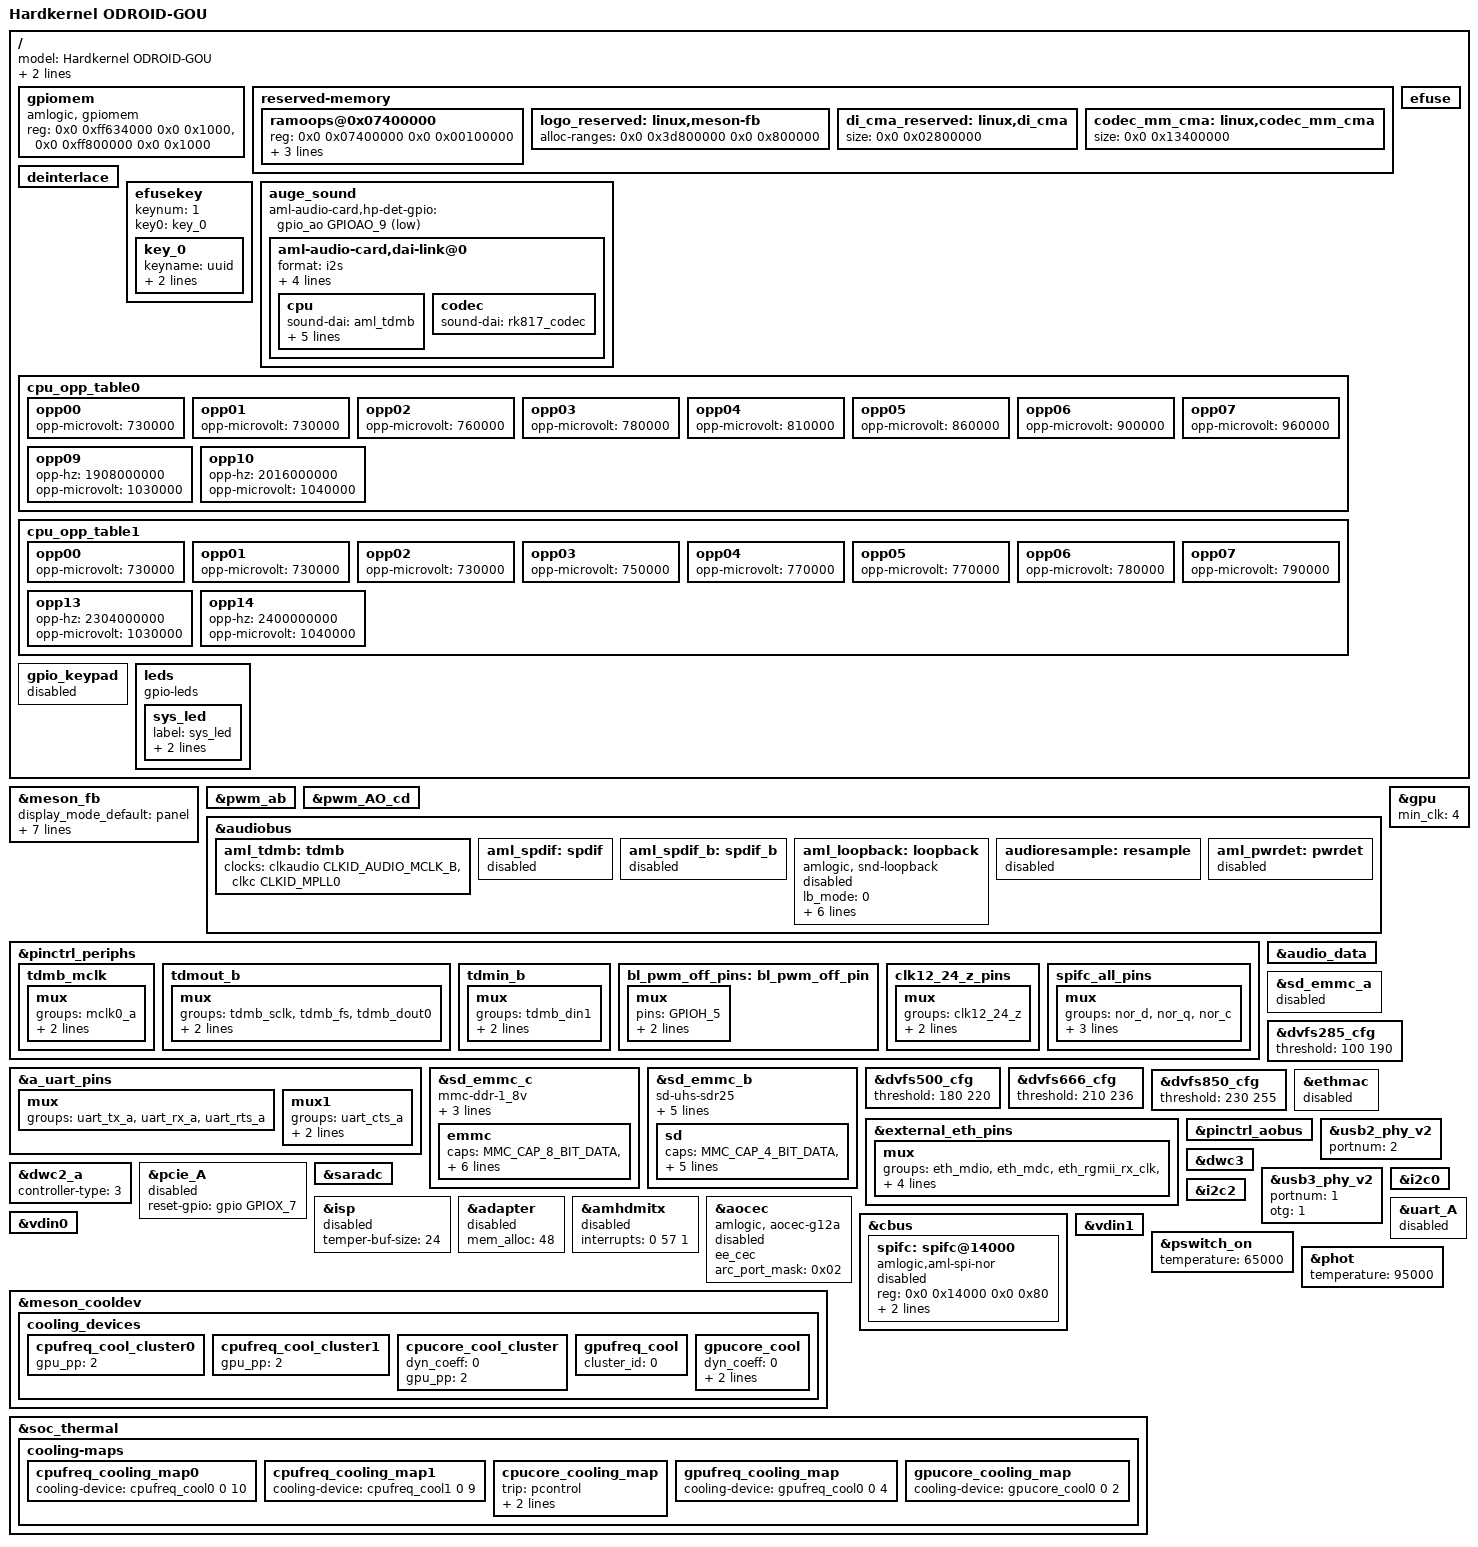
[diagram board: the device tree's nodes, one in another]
// All g12b devices should base on either coreelec_g12b.dtsi or coreelec_g12b_a.dtsi
#include "coreelec_g12b.dtsi"
// OGU specific: Power Management Integrated Controller
#include "meson64_gou_pmic.dtsi"
// OGU specific: LCD panel
#include "meson64_gou_panel.dtsi"
// OGU specific: GPIO Joypad
#include "meson64_gou_joypad.dtsi"

/ {
	model = "Hardkernel ODROID-GOU";
	coreelec-dt-id = "g12b_s922x_odroid_go_ultra"; // Yeah we will still use coreelec-dt-id, never re-invent the wheel huh?
	amlogic-dt-id = "g12b_ogu";

	/delete-node/ bt-dev; // No BT or Wi-Fi included
	/delete-node/ wifi;
	/delete-node/ wifi_pwm_conf;
	/delete-node/ adc_keypad;
	/delete-node/ unifykey;
	// /delete-node/ rtc;
	/delete-node/ videosync;
	/delete-node/ dummy_venc;
	/delete-node/ video_composer;
	/delete-node/ meson_uvm;
	/delete-node/ vcodec_dec;
	/delete-node/ jpegenc;
	/delete-node/ gpioleds;
	/delete-node/ cvbsout;
	/delete-node/ linux,picdec;
	/delete-node/ picdec;
	/delete-node/ multi-di;
	/delete-node/ meson-ir;
	/delete-node/ meson-remote;
	/delete-node/ openvfd;
	/delete-node/ amvideocap;

	gpiomem {
		compatible = "amlogic, gpiomem";
		reg = <0x0 0xff634000 0x0 0x1000>,	/* GPIO banks */
			<0x0 0xff800000 0x0 0x1000>;	/* GPIO_AO bank */
		status = "okay";
	};

	reserved-memory {
		#address-cells = <2>;
		#size-cells = <2>;
		ranges;

		/* global autoconfigured region for contiguous allocations */
		ramoops@0x07400000 {
			reg = <0x0 0x07400000 0x0 0x00100000>;
			record-size = <0x8000>;
			console-size = <0x8000>;
			ftrace-size = <0x40000>;
		};

		logo_reserved:linux,meson-fb {
			alloc-ranges = <0x0 0x3d800000 0x0 0x800000>;
		};

		/*di CMA pool */
		di_cma_reserved:linux,di_cma {
			/* buffer_size = 3621952(yuv422 8bit)
			 *  | 4736064(yuv422 10bit)
			 *  | 4074560(yuv422 10bit full pack mode)
			 * 10x3621952=34.6M(0x23) support 8bit
			 * 10x4736064=45.2M(0x2e) support 12bit
			 * 10x4074560=40M(0x28) support 10bit
			 */
			size = <0x0 0x02800000>;
		};

		codec_mm_cma:linux,codec_mm_cma {
			/* ion_codec_mm max can alloc size 80M*/
			size = <0x0 0x13400000>;
		};	
	};

	deinterlace {
		status = "okay";
	};

	efuse: efuse{
		status = "okay";
	};

	efusekey:efusekey{
		keynum = <1>;
		key0 = <&key_0>;
		/delete-property/ key1;
		/delete-property/ key2;
		/delete-property/ key3;
		/delete-node/ key_1;
		/delete-node/ key_2;
		/delete-node/ key_3;

		key_0: key_0 {
			keyname = "uuid";
			offset = <0>;
			size = <32>;
		};
	};//End efusekey

	/* Audio Related start */
	auge_sound {
		aml-audio-card,hp-det-gpio = <&gpio_ao GPIOAO_9 GPIO_ACTIVE_LOW>;
		/delete-property/ avout_mute-gpios;
		/delete-node/ aml-audio-card,dai-link@1;
		/delete-node/ aml-audio-card,dai-link@2;
		/delete-node/ aml-audio-card,dai-link@3;
		aml-audio-card,dai-link@0 {
			format = "i2s";
			mclk-fs = <256>;
			bitclock-master = <&aml_tdmb>;
			frame-master = <&aml_tdmb>;
			continuous-clock;

			cpu {
				sound-dai = <&aml_tdmb>;
				dai-tdm-slot-tx-mask = <1 1>;
				dai-tdm-slot-rx-mask = <1 1>;
				dai-tdm-slot-num = <2>;
				dai-tdm-slot-width = <32>;
				system-clock-frequency = <12288000>;
			};
			codec {
				sound-dai = <&rk817_codec>;
			};
		};
	};
	/* Audio Related end */

	cpu_opp_table0: cpu_opp_table0 {
		opp00 {
			opp-microvolt = <730000>;
		};
		opp01 {
			opp-microvolt = <730000>;
		};
		opp02 {
			opp-microvolt = <760000>;
		};
		opp03 {
			opp-microvolt = <780000>;
		};
		opp04 {
			opp-microvolt = <810000>;
		};
		opp05 {
			opp-microvolt = <860000>;
		};
		opp06 {
			opp-microvolt = <900000>;
		};
		opp07 {
			opp-microvolt = <960000>;
		};
		opp09 {
			opp-hz = /bits/ 64 <1908000000>;
			opp-microvolt = <1030000>;
		};
		opp10 {
			opp-hz = /bits/ 64 <2016000000>;
			opp-microvolt = <1040000>;
		};
	};

	cpu_opp_table1: cpu_opp_table1 {
		opp00 {
			opp-microvolt = <730000>;
		};
		opp01 {
			opp-microvolt = <730000>;
		};
		opp02 {
			opp-microvolt = <730000>;
		};
		opp03 {
			opp-microvolt = <750000>;
		};
		opp04 {
			opp-microvolt = <770000>;
		};
		opp05 {
			opp-microvolt = <770000>;
		};
		opp06 {
			opp-microvolt = <780000>;
		};
		opp07 {
			opp-microvolt = <790000>;
		};
		opp13 {
			opp-hz = /bits/ 64 <2304000000>;
			opp-microvolt = <1030000>;
		};
		opp14 {
			opp-hz = /bits/ 64 <2400000000>;
			opp-microvolt = <1040000>;
		};
	};

	gpio_keypad {
		status = "disabled";
	};

	leds {
		compatible = "gpio-leds";
		status = "okay";
		sys_led {
			label="sys_led";
			gpios=<&gpio_ao GPIOAO_11 GPIO_ACTIVE_HIGH>;
			linux,default-trigger = "heartbeat";
		};
	};
}; /* end of / */

&meson_fb {
	status = "okay";
	display_mode_default = "panel";
	display_size_default = <480 854 480 1708 32>;
	mem_size = <0x00800000 0x4b80000 0x100000 0x100000 0x800000>;
	logo_addr = "0x3d800000";
	mem_alloc = <1>;
	pxp_mode = <0>; /** 0:normal mode 1:pxp mode */
	4k2k_fb = <0>;
};

&pwm_ab {
	status = "okay";
};

&pwm_AO_cd {
	status = "okay";
};

&audiobus {
	/* tdmb to internal DAC output*/
	/delete-node/ loopback@0;
	/delete-node/ i2s2hdmi;
	aml_tdmb: tdmb {
		clocks = <&clkaudio CLKID_AUDIO_MCLK_B
				&clkc CLKID_MPLL0>;
		clock-names = "mclk", "clk_srcpll";
		/delete-property/ samesource_sel;
	};
	aml_spdif: spdif {
		status = "disabled";
	};
	aml_spdif_b: spdif_b {
		status = "disabled";
	};
	aml_loopback: loopback {
		compatible = "amlogic, snd-loopback";
		/*
		 * 0: out rate = in data rate;
		 * 1: out rate = loopback data rate;
		 */
		lb_mode = <0>;

		/* datain src
		 * 0: tdmin_a;
		 * 1: tdmin_b;
		 * 2: tdmin_c;
		 * 3: spdifin;
		 * 4: pdmin;
		 */
		datain_src = <4>;
		datain_chnum = <8>;
		datain_chmask = <0x3f>;

		/* tdmin_lb src
		 * 0: tdmoutA
		 * 1: tdmoutB
		 * 2: tdmoutC
		 * 3: PAD_tdminA
		 * 4: PAD_tdminB
		 * 5: PAD_tdminC
		 */
		datalb_src = <2>;
		datalb_chnum = <8>;
		datalb_chmask = <0x3>;

		status = "disabled";
	};

	audioresample: resample {
		status = "disabled";
	};
	aml_pwrdet: pwrdet {
		status = "disabled";
	};
}; /* end of audiobus */

&pinctrl_periphs {
	tdmb_mclk: tdmb_mclk {
		mux { /* GPIOA_0 */
			groups = "mclk0_a";
			function = "mclk0";
			drive-strength = <2>;
		};
	};
	tdmout_b: tdmout_b {
		mux { /* GPIOA_1, GPIOA_2, GPIOA_3 */
			groups = "tdmb_sclk",
				"tdmb_fs",
				"tdmb_dout0";
			function = "tdmb_out";
			drive-strength = <2>;
		};
	};
	tdmin_b:tdmin_b {
		mux { /* GPIOA_4 */
			groups = "tdmb_din1";
			function = "tdmb_in";
			drive-strength = <2>;
		};
	};

	bl_pwm_off_pins:bl_pwm_off_pin {
		mux {
			pins = "GPIOH_5";
			function = "gpio_periphs";
			output-high;
		};
	};

	clk12_24_z_pins:clk12_24_z_pins {
		mux {
			groups = "clk12_24_z";
			function = "clk12_24_ee";
			drive-strength = <3>;
		};
	};

	spifc_all_pins: spifc_all_pins {
		mux {
			groups = "nor_d",
				"nor_q",
				"nor_c";
			function = "nor";
			input-enable;
			bias-pull-up;
		};
	};
}; /* end of pinctrl_periphs */

&a_uart_pins {
	mux {
		groups = "uart_tx_a",
			"uart_rx_a",
			"uart_rts_a";
	};
	mux1 {
		groups = "uart_cts_a";
		function = "uart_a";
		bias-pull-down;
	};
};

&audio_data {
	status = "okay";
};

&sd_emmc_c {
	status = "okay";
	mmc-ddr-1_8v;
	mmc-hs200-1_8v;
	vmmc-supply = <&vcc_sd>;
	vqmmc-supply = <&vddio_ao1v8>;
	emmc {
		caps = "MMC_CAP_8_BIT_DATA",
			 "MMC_CAP_MMC_HIGHSPEED",
			 "MMC_CAP_SD_HIGHSPEED",
			 "MMC_CAP_NONREMOVABLE",
			 "MMC_CAP_HW_RESET",
			 "MMC_CAP_ERASE",
			 "MMC_CAP_CMD23";
		caps2 = "MMC_CAP2_HS200_1_8V_SDR",
			"MMC_CAP2_BROKEN_VOLTAGE";
		hw_reset = <&gpio BOOT_12 GPIO_ACTIVE_HIGH>;
	};
};

&sd_emmc_b {
	status = "okay";
	sd-uhs-sdr25;
	sd-uhs-sdr50;
	sd-uhs-sdr104;
	max-frequency = <200000000>;
	vmmc-supply = <&vcc_sd>;
	vqmmc-supply = <&vddio_c>;
	sd {
		caps = "MMC_CAP_4_BIT_DATA",
			 "MMC_CAP_MMC_HIGHSPEED",
			 "MMC_CAP_SD_HIGHSPEED",
			 "MMC_CAP_UHS_SDR25",
			 "MMC_CAP_UHS_SDR50",
			 "MMC_CAP_UHS_SDR104",
			 "MMC_CAP_ERASE",
			 "MMC_CAP_CMD23";
		f_max = <200000000>;
	};
};

&sd_emmc_a {
	status = "disabled";
	/delete-node/ sdio;
};

&gpu {
	min_clk = <4>;
};

&dvfs285_cfg {
   threshold = <100 190>;
};

&dvfs500_cfg {
   threshold = <180 220>;
};

&dvfs666_cfg {
   threshold = <210 236>;
};

&dvfs850_cfg {
   threshold = <230 255>;
};

&ethmac {
	status = "disabled";
	/delete-property/ mc_val;
	/delete-property/ internal_phy;
	/delete-property/ pinctrl-names;
	/delete-property/ pinctrl-0;
};

&external_eth_pins {
	mux {
		groups = "eth_mdio",
		"eth_mdc",
		"eth_rgmii_rx_clk",
		"eth_rx_dv",
		"eth_rxd0",
		"eth_rxd1",
		"eth_rxd2_rgmii",
		"eth_rxd3_rgmii",
		"eth_rgmii_tx_clk",
		"eth_txen",
		"eth_txd0",
		"eth_txd1",
		"eth_txd2_rgmii",
		"eth_txd3_rgmii";
	};
};

&pinctrl_aobus {
	/delete-node/ spdifout;
	/delete-node/ spdifout_a_mute;
};

&aml_spdif {
	/delete-property/ pinctrl-0;
	/delete-property/ pinctrl-1;
};

&usb2_phy_v2 {
	status = "okay";
	portnum = <2>;
};

&dwc3 {
	status = "okay";
};

&dwc2_a {
	status = "okay";
	/** 0: normal, 1: otg+dwc3 host only, 2: otg+dwc3 device only*/
	controller-type = <3>;
};

&pcie_A {
	reset-gpio = <&gpio GPIOX_7 GPIO_ACTIVE_HIGH>;
	status = "disabled";
	clock-names = "pcie_refpll",
				"pcie",
				"pcie_phy";
};

&usb3_phy_v2 {
	status = "okay";
	portnum = <1>;
	otg = <1>;
	/delete-property/ gpio-vbus-power;
	/delete-property/ gpios;
};

&saradc {
	status = "okay";
};

&i2c0 {
	/delete-property/ pinctrl-names;
	/delete-property/ pinctrl-0;
	/delete-property/ clock-frequency;
};

&i2c2 {
	/delete-property/ pinctrl-names;
	/delete-property/ pinctrl-0;
	/delete-property/ clock-frequency;
};

&isp {
	status = "disabled";
	temper-buf-size = <24>;
	/delete-property/ temper-line-offset;
	/delete-property/ temper-frame-num;
	/delete-property/ temper-frame-size;
	/delete-property/ memory-region;
};

&adapter {
	status = "disabled";
	mem_alloc = <48>;
	/delete-property/ memory-region;
};

&amhdmitx {
	status = "disabled";
	interrupts = <0 57 1>;
	interrupt-names = "hdmitx_hpd";
};

&aocec {
	status = "disabled";
	compatible = "amlogic, aocec-g12a";
	ee_cec;
	arc_port_mask = <0x02>;
	/delete-property/ output;
};

&cbus {
	spifc: spifc@14000 {
		status = "disabled";
		compatible = "amlogic,aml-spi-nor";
		reg = <0x0 0x14000 0x0 0x80>;
		pinctrl-names = "default";
		pinctrl-0 = <&spifc_all_pins>;
		clocks = <&clkc 11>;
		clock-names = "core";
   };
};

&uart_A {
	status = "disabled";
};

&vdin0 {
	/delete-property/ cma_size;
	/delete-property/ tv_bit_mode;
};

&vdin1 {
	/delete-property/ memory-region;
	/delete-property/ tv_bit_mode;
};

&meson_cooldev {
	cooling_devices {
		cpufreq_cool_cluster0 {
			gpu_pp = <2>;
		};
		cpufreq_cool_cluster1 {
			gpu_pp = <2>;
		};
		cpucore_cool_cluster {
			dyn_coeff = <0>;
			gpu_pp = <2>;
		};
		gpufreq_cool {
			cluster_id = <0>;
		};
		gpucore_cool {
			dyn_coeff = <0>;
			cluster_id = <0>;
			gpu_pp = <2>;
		};
	};
};

&pswitch_on {
	temperature = <65000>;
};

&phot {
	temperature = <95000>;
};

&soc_thermal {
	cooling-maps {
		/delete-node/ cpucore_cooling_map0;
		cpufreq_cooling_map0 {
			cooling-device = <&cpufreq_cool0 0 10>;
		};
		cpufreq_cooling_map1 {
			cooling-device = <&cpufreq_cool1 0 9>;
		};
		cpucore_cooling_map {
			trip = <&pcontrol>;
			cooling-device = <&cpucore_cool 0 5>;
			contribution = <1024>;
		};
		gpufreq_cooling_map {
			cooling-device = <&gpufreq_cool0 0 4>;
		};
		gpucore_cooling_map {
			cooling-device = <&gpucore_cool0 0 2>;
		};
	};
};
